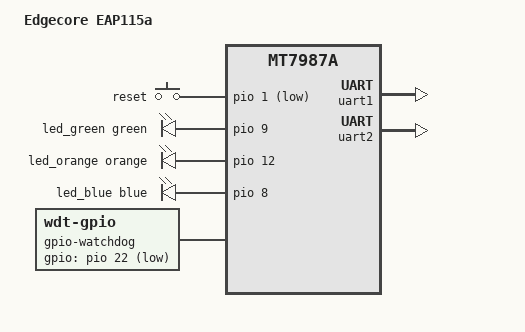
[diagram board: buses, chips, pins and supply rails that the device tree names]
// SPDX-License-Identifier: (GPL-2.0 OR MIT)
/*
 * Copyright (C) 2025 MediaTek Inc.
 * Author: Sam.Shih <sam.shih@mediatek.com>
 */

/dts-v1/;
#include "mt7987a.dtsi"
#include <dt-bindings/input/input.h>

/* MT7987A RFB DTS for DT overlay-based device tree */
/ {
	model = "Edgecore EAP115a";
	compatible = "edgecore,eap115a";

	aliases {
		serial0 = &uart0;
		led-boot = &led_green;
		led-failsafe = &led_green;
		led-running = &led_green;
		led-upgrade = &led_green;
		label-mac-device = &gmac1;
	};

	chosen {
		bootargs = "console=ttyS0,115200n1 loglevel=7  \
			    earlycon=uart8250,mmio32,0x11000000 \
			    pci=pcie_bus_perf";
	};

	gpio-keys {
		compatible = "gpio-keys";

		reset {
			label = "reset";
			linux,code = <KEY_RESTART>;
			gpios = <&pio 1 GPIO_ACTIVE_LOW>;
			debounce-interval = <10>;
		};
	};

	leds {
		compatible = "gpio-leds";

		led_green: led-green {
			gpios = <&pio 9 GPIO_ACTIVE_HIGH>;
			color = <LED_COLOR_ID_GREEN>;
			function = LED_FUNCTION_INDICATOR;
		};

		led_orange: led-orange {
			gpios = <&pio 12 GPIO_ACTIVE_HIGH>;
			color = <LED_COLOR_ID_ORANGE>;
			function = LED_FUNCTION_INDICATOR;
		};

		led_blue: led-blue {
			gpios = <&pio 8 GPIO_ACTIVE_HIGH>;
			color = <LED_COLOR_ID_BLUE>;
			function = LED_FUNCTION_INDICATOR;
		};
	};

	gpio-watchdog {
		compatible = "linux,wdt-gpio";
		gpios = <&pio 22 GPIO_ACTIVE_LOW>;
		hw_algo = "level";
		hw_margin_ms = <1000>;
		always-running;
	};

	reserved-memory {
		/* 128 KiB reserved for ramoops/pstore */
		ramoops@5ffa0000 {
			compatible = "ramoops";
			reg = <0 0x5ffa0000 0 0x20000>;
			ecc-size = <0x0>;
			record-size = <0x4000>;
			console-size = <0x4000>;
			pmsg-size = <0x4000>;
			ftrace-size = <0x0>;
		};
	};
};

&afe {
	pinctrl-names = "default";
	pinctrl-0 = <&pcm_pins>;
	status = "disabled";
};

&fan {
	pwms = <&pwm 0 50000 0>;
	status = "disabled";
};

&pcie0 {
	slot0: pcie@0,0 {
		reg = <0x0000 0 0 0 0>;
	};
};

&pcie1 {
	pinctrl-names = "default";
	pinctrl-0 = <&pcie1_pins>;
	status = "disabled";
};

&eth {
	/delete-node/ mac@2;
};

&uart1 {
	pinctrl-names = "default";
	pinctrl-0 = <&uart1_pins>;
	status = "okay";
};

&uart2 {
	pinctrl-names = "default";
	pinctrl-0 = <&uart2_pins>;
	status = "okay";
};
